# STM32F413xx register map
File version: 1.0
Registers are 32-bit, read-write, reset 0x0 unless marked. A register's access mark holds for its fields unless they carry their own. Offsets are from the block's base; [hi:lo] are bit positions.

## USART2 — Universal Synchronous Asynchronous Receiver Transmitter
Base 0x40004400
Same registers: USART3 0x40004800, USART1 0x40011000, USART6 0x40011400
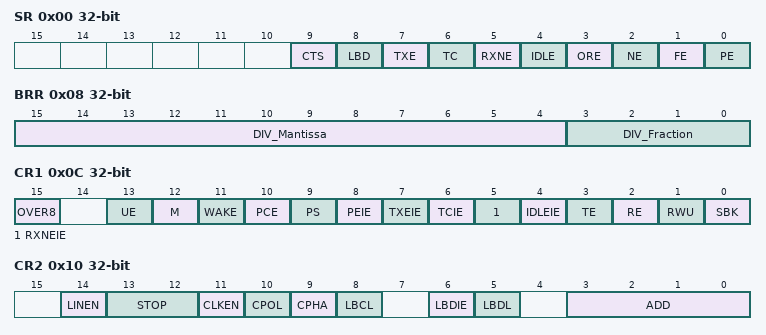
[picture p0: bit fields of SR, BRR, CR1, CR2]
0x00 SR — USART Status register
  [9] CTS — CTS Flag
  [8] LBD — LIN Break Detection Flag
  [7] TXE — Transmit Data Register Empty
  [6] TC — Transmission Complete
  [5] RXNE — Read Data Register Not Empty
  [4] IDLE — IDLE line detected
  [3] ORE — OverRun Error
  [2] NE — Noise Error Flag
  [1] FE — Framing Error
  [0] PE — Parity Error
0x04 DR — USART Data register
  [8:0] DR — Data value
0x08 BRR — USART Baud rate register
  [15:4] DIV_Mantissa — Mantissa of USARTDIV
  [3:0] DIV_Fraction — Fraction of USARTDIV
0x0C CR1 — USART Control register 1
  [15] OVER8 — USART Oversampling by 8 enable
    0=OVERSAMPLING_16 (Oversampling by 16); 1=OVERSAMPLING_8 (Oversampling by 8)
  [13] UE — USART Enable
  [12] M — Word length
    0=DATAWIDTH_8B (8 bits word length : Start bit, 8 data bits, n stop bits); 1=DATAWIDTH_9B (9 bits word length : Start bit, 9 data bits, n stop bits)
  [11] WAKE — Wakeup method
    0=IDLELINE (USART wake up from Mute mode on Idle Line); 1=ADDRESSMARK (USART wake up from Mute mode on Address Mark)
  [10] PCE — Parity Control Enable
  [9] PS — Parity Selection
  [8] PEIE — PE Interrupt Enable
  [7] TXEIE — TXE Interrupt Enable
  [6] TCIE — Transmission Complete Interrupt Enable
  [5] RXNEIE — RXNE Interrupt Enable
  [4] IDLEIE — IDLE Interrupt Enable
  [3] TE — Transmitter Enable
  [2] RE — Receiver Enable
  [1] RWU — Receiver wakeup
  [0] SBK — Send Break
0x10 CR2 — USART Control register 2
  [14] LINEN — LIN mode enable
  [13:12] STOP — STOP[1:0] bits (STOP bits)
    1=STOPBITS_0_5 (0.5 stop bit); 0=STOPBITS_1 (1 stop bit); 3=STOPBITS_1_5 (1.5 stop bits); 2=STOPBITS_2 (2 stop bits)
  [11] CLKEN — Clock Enable
  [10] CPOL — Clock Polarity
    0=LOW (Steady low value on SCLK pin outside transmission window); 1=HIGH (Steady high value on SCLK pin outside transmission window)
  [9] CPHA — Clock Phase
    0=PHASE_1EDGE (The first clock transition is the first data capture edge); 1=PHASE_2EDGE (The second clock transition is the first data capture edge)
  [8] LBCL — Last Bit Clock pulse
    0=NO_OUTPUT (The clock pulse of the last data bit is not output to the SCLK pin); 1=OUTPUT (The clock pulse of the last data bit is output to the SCLK pin)
  [6] LBDIE — LIN Break Detection Interrupt Enable
  [5] LBDL — LIN Break Detection Length
    0=DETECT_10B (10-bit break detection method selected); 1=DETECT_11B (11-bit break detection method selected)
  [3:0] ADD — Address of the USART node
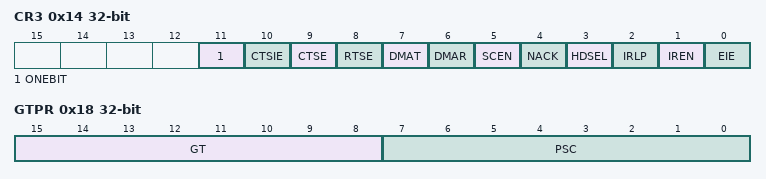
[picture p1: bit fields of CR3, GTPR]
0x14 CR3 — USART Control register 3
  [11] ONEBIT — USART One bit method enable
  [10] CTSIE — CTS Interrupt Enable
  [9] CTSE — CTS Enable
  [8] RTSE — RTS Enable
  [7] DMAT — DMA Enable Transmitter
  [6] DMAR — DMA Enable Receiver
  [5] SCEN — Smartcard mode enable
  [4] NACK — Smartcard NACK enable
  [3] HDSEL — Half-Duplex Selection
  [2] IRLP — IrDA Low-Power
    0=NORMAL (IrDA normal power mode); 1=LOW (IrDA low power mode)
  [1] IREN — IrDA mode Enable
  [0] EIE — Error Interrupt Enable
0x18 GTPR — USART Guard time and prescaler register
  [15:8] GT — Guard time value
  [7:0] PSC — PSC[7:0] bits (Prescaler value)

## UART4 — Universal Synchronous Asynchronous Receiver Transmitter
Base 0x40004C00
Same registers: UART5 0x40005000, UART7 0x40007800, UART8 0x40007C00, UART9 0x40011800, UART10 0x40011C00
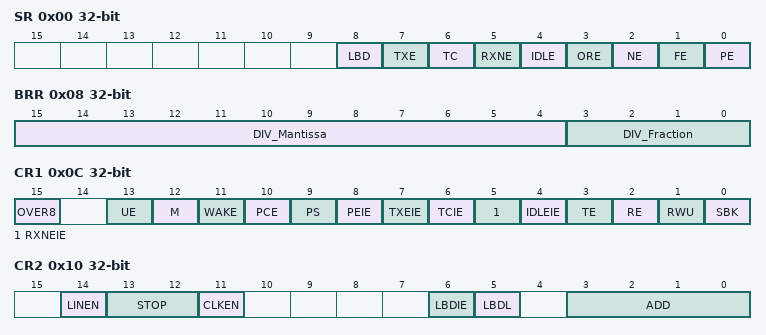
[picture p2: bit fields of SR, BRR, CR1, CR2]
0x00 SR — USART Status register
  [8] LBD — LIN Break Detection Flag
  [7] TXE — Transmit Data Register Empty
  [6] TC — Transmission Complete
  [5] RXNE — Read Data Register Not Empty
  [4] IDLE — IDLE line detected
  [3] ORE — OverRun Error
  [2] NE — Noise Error Flag
  [1] FE — Framing Error
  [0] PE — Parity Error
0x04 DR — USART Data register
  [8:0] DR — Data value
0x08 BRR — USART Baud rate register
  [15:4] DIV_Mantissa — Mantissa of USARTDIV
  [3:0] DIV_Fraction — Fraction of USARTDIV
0x0C CR1 — USART Control register 1
  [15] OVER8 — USART Oversampling by 8 enable
    0=OVERSAMPLING_16 (Oversampling by 16); 1=OVERSAMPLING_8 (Oversampling by 8)
  [13] UE — USART Enable
  [12] M — Word length
    0=DATAWIDTH_8B (8 bits word length : Start bit, 8 data bits, n stop bits); 1=DATAWIDTH_9B (9 bits word length : Start bit, 9 data bits, n stop bits)
  [11] WAKE — Wakeup method
    0=IDLELINE (USART wake up from Mute mode on Idle Line); 1=ADDRESSMARK (USART wake up from Mute mode on Address Mark)
  [10] PCE — Parity Control Enable
  [9] PS — Parity Selection
  [8] PEIE — PE Interrupt Enable
  [7] TXEIE — TXE Interrupt Enable
  [6] TCIE — Transmission Complete Interrupt Enable
  [5] RXNEIE — RXNE Interrupt Enable
  [4] IDLEIE — IDLE Interrupt Enable
  [3] TE — Transmitter Enable
  [2] RE — Receiver Enable
  [1] RWU — Receiver wakeup
  [0] SBK — Send Break
0x10 CR2 — USART Control register 2
  [14] LINEN — LIN mode enable
  [13:12] STOP — STOP[1:0] bits (STOP bits)
    1=STOPBITS_0_5 (0.5 stop bit); 0=STOPBITS_1 (1 stop bit); 3=STOPBITS_1_5 (1.5 stop bits); 2=STOPBITS_2 (2 stop bits)
  [11] CLKEN — Clock Enable
  [6] LBDIE — LIN Break Detection Interrupt Enable
  [5] LBDL — LIN Break Detection Length
    0=DETECT_10B (10-bit break detection method selected); 1=DETECT_11B (11-bit break detection method selected)
  [3:0] ADD — Address of the USART node
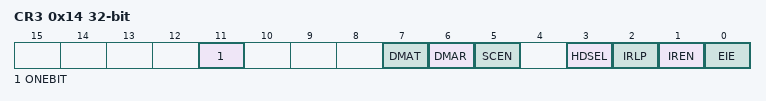
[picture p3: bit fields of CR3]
0x14 CR3 — USART Control register 3
  [11] ONEBIT — USART One bit method enable
  [7] DMAT — DMA Enable Transmitter
  [6] DMAR — DMA Enable Receiver
  [5] SCEN — Smartcard mode enable
  [3] HDSEL — Half-Duplex Selection
  [2] IRLP — IrDA Low-Power
    0=NORMAL (IrDA normal power mode); 1=LOW (IrDA low power mode)
  [1] IREN — IrDA mode Enable
  [0] EIE — Error Interrupt Enable
0x18 GTPR — USART Guard time and prescaler register
  [7:0] PSC — PSC[7:0] bits (Prescaler value)
